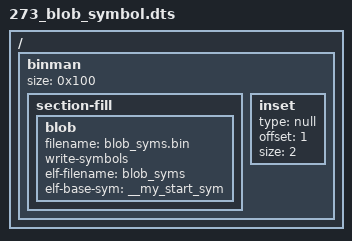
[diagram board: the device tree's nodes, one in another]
/dts-v1/;

/ {
	#address-cells = <1>;
	#size-cells = <1>;

	binman {
		size = <0x100>;
		section-fill {
			blob {
				filename = "blob_syms.bin";
				write-symbols;
				elf-filename = "blob_syms";
				elf-base-sym = "__my_start_sym";
			};
		};

		inset {
			type = "null";
			offset = <1>;
			size = <2>;
		};
	};
};
